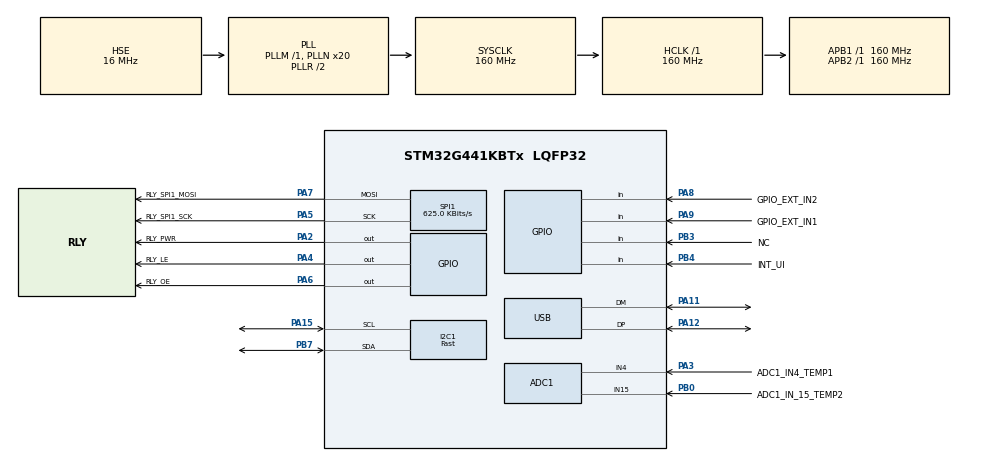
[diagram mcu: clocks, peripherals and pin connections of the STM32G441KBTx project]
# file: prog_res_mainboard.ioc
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ADC1.Channel-0\#ChannelRegularConversion=ADC_CHANNEL_VREFINT
ADC1.Channel-1\#ChannelRegularConversion=ADC_CHANNEL_TEMPSENSOR_ADC1
ADC1.Channel-2\#ChannelRegularConversion=ADC_CHANNEL_4
ADC1.Channel-3\#ChannelRegularConversion=ADC_CHANNEL_15
ADC1.ClockPrescaler=ADC_CLOCK_ASYNC_DIV16
ADC1.ContinuousConvMode=ENABLE
ADC1.DMAContinuousRequests=ENABLE
ADC1.NbrOfConversion=4
ADC1.NbrOfConversionFlag=1
ADC1.OffsetNumber-0\#ChannelRegularConversion=ADC_OFFSET_NONE
ADC1.OffsetNumber-1\#ChannelRegularConversion=ADC_OFFSET_NONE
ADC1.OffsetNumber-2\#ChannelRegularConversion=ADC_OFFSET_NONE
ADC1.OffsetNumber-3\#ChannelRegularConversion=ADC_OFFSET_NONE
ADC1.OversamplingMode=ENABLE
ADC1.Rank-0\#ChannelRegularConversion=1
ADC1.Rank-1\#ChannelRegularConversion=2
ADC1.Rank-2\#ChannelRegularConversion=3
ADC1.Rank-3\#ChannelRegularConversion=4
ADC1.Ratio=ADC_OVERSAMPLING_RATIO_256
ADC1.RightBitShift=ADC_RIGHTBITSHIFT_4
ADC1.SamplingTime-0\#ChannelRegularConversion=ADC_SAMPLETIME_640CYCLES_5
ADC1.SamplingTime-1\#ChannelRegularConversion=ADC_SAMPLETIME_640CYCLES_5
ADC1.SamplingTime-2\#ChannelRegularConversion=ADC_SAMPLETIME_640CYCLES_5
ADC1.SamplingTime-3\#ChannelRegularConversion=ADC_SAMPLETIME_640CYCLES_5
ADC1.master=1
Dma.ADC1.0.Direction=DMA_PERIPH_TO_MEMORY
Dma.ADC1.0.EventEnable=DISABLE
Dma.ADC1.0.Instance=DMA2_Channel1
Dma.ADC1.0.MemDataAlignment=DMA_MDATAALIGN_WORD
Dma.ADC1.0.MemInc=DMA_MINC_ENABLE
Dma.ADC1.0.Mode=DMA_CIRCULAR
Dma.ADC1.0.PeriphDataAlignment=DMA_PDATAALIGN_WORD
Dma.ADC1.0.PeriphInc=DMA_PINC_DISABLE
Dma.ADC1.0.Polarity=HAL_DMAMUX_REQ_GEN_RISING
Dma.ADC1.0.Priority=DMA_PRIORITY_LOW
Dma.ADC1.0.RequestNumber=1
Dma.ADC1.0.SignalID=NONE
Dma.ADC1.0.SyncEnable=DISABLE
Dma.ADC1.0.SyncPolarity=HAL_DMAMUX_SYNC_NO_EVENT
Dma.ADC1.0.SyncRequestNumber=1
Dma.ADC1.0.SyncSignalID=NONE
Dma.Request0=ADC1
FREERTOS.INCLUDE_uxTaskGetStackHighWaterMark=1
FREERTOS.INCLUDE_uxTaskPriorityGet=1
FREERTOS.INCLUDE_vTaskDelete=1
FREERTOS.INCLUDE_vTaskPrioritySet=1
FREERTOS.INCLUDE_xQueueGetMutexHolder=0
FREERTOS.INCLUDE_xSemaphoreGetMutexHolder=1
FREERTOS.INCLUDE_xTaskGetSchedulerState=1
FREERTOS.INCLUDE_xTaskResumeFromISR=0
FREERTOS.Mutexes01=i2cMutex,Static,i2cMutexControlBlock
FREERTOS.Queues01=keycodeQueue,16,uint8_t,0,Static,keycodeQueueBuffer,keycodeQueueControlBlock;encoderQueue,16,int16_t,0,Static,encoderQueueBuffer,encoderQueueControlBlock
FREERTOS.Tasks01=scpiTask,32,512,BASE_StartScpiTask,As weak,NULL,Static,scpiTaskBuffer,scpiTaskControlBlock;uiTask,24,512,BASE_StartUiTask,As weak,NULL,Static,uiTaskBuffer,uiTaskControlBlock
FREERTOS.Timers01=timer10ms,BASE_TimerTick_10ms,osTimerPeriodic,As weak,NULL,Static,timer10msControlBlock
FREERTOS.configENABLE_FPU=1
FREERTOS.configTOTAL_HEAP_SIZE=512
FREERTOS.configUSE_NEWLIB_REENTRANT=1
I2C1.CustomTiming=Disabled
I2C1.I2C_Fall_Time=300
I2C1.I2C_Rise_Time=300
I2C1.I2C_Speed_Mode=I2C_Fast
I2C1.Speed=200
I2C1.Timing=0x30FA1594
Mcu.Family=STM32G4
Mcu.Name=STM32G441KBTx
Mcu.Package=LQFP32
NVIC.ADC1_2_IRQn=true\:5\:0\:false\:false\:true\:true\:true\:true\:true
NVIC.DMA2_Channel1_IRQn=true\:5\:0\:false\:false\:true\:true\:false\:true\:true
NVIC.I2C1_ER_IRQn=true\:5\:0\:false\:false\:true\:true\:true\:true\:true
NVIC.I2C1_EV_IRQn=true\:5\:0\:false\:false\:true\:true\:true\:true\:true
NVIC.PriorityGroup=NVIC_PRIORITYGROUP_4
NVIC.SPI1_IRQn=true\:5\:0\:false\:false\:true\:true\:true\:true\:true
NVIC.TIM6_DAC_IRQn=true\:15\:0\:false\:false\:true\:false\:false\:true\:true
NVIC.TIM7_IRQn=true\:5\:0\:false\:false\:true\:true\:true\:true\:true
NVIC.TimeBase=TIM6_DAC_IRQn
NVIC.TimeBaseIP=TIM6
NVIC.USB_LP_IRQn=true\:5\:0\:false\:false\:true\:true\:false\:true\:true
PA11.Mode=Device
PA11.Signal=USB_DM
PA12.Mode=Device
PA12.Signal=USB_DP
PA13.Mode=Serial_Wire
PA13.Signal=SYS_JTMS-SWDIO
PA14.Mode=Serial_Wire
PA14.Signal=SYS_JTCK-SWCLK
PA15.Mode=I2C
PA15.Signal=I2C1_SCL
PA2.GPIO_Label=RLY_PWR
PA2.Signal=GPIO_Output
PA3.GPIO_Label=ADC1_IN4_TEMP1
PA3.Mode=IN4-Single-Ended
PA3.Signal=ADC1_IN4
PA4.GPIO_Label=RLY_LE
PA4.Signal=GPIO_Output
PA5.GPIO_Label=RLY_SPI1_SCK
PA5.Mode=TX_Only_Simplex_Unidirect_Master
PA5.Signal=SPI1_SCK
PA6.GPIO_Label=RLY_OE
PA6.Signal=GPIO_Output
PA7.GPIO_Label=RLY_SPI1_MOSI
PA7.Mode=TX_Only_Simplex_Unidirect_Master
PA7.Signal=SPI1_MOSI
PA8.GPIO_Label=GPIO_EXT_IN2
PA8.Signal=GPIO_Input
PA9.GPIO_Label=GPIO_EXT_IN1
PA9.Signal=GPIO_Input
PB0.GPIO_Label=ADC1_IN_15_TEMP2
PB0.Mode=IN15-Single-Ended
PB0.Signal=ADC1_IN15
PB3.GPIO_Label=NC
PB3.Signal=GPIO_Input
PB4.GPIO_Label=INT_UI
PB4.Signal=GPIO_Input
PB7.Mode=I2C
PB7.Signal=I2C1_SDA
PF0-OSC_IN.Mode=HSE-External-Oscillator
PF0-OSC_IN.Signal=RCC_OSC_IN
PF1-OSC_OUT.Mode=HSE-External-Oscillator
PF1-OSC_OUT.Signal=RCC_OSC_OUT
ProjectManager.HeapSize=0x180
ProjectManager.StackSize=0x300
ProjectManager.TargetToolchain=STM32CubeIDE
RCC.ADC12Freq_Value=160000000
RCC.AHBFreq_Value=160000000
RCC.APB1Freq_Value=160000000
RCC.APB1TimFreq_Value=160000000
RCC.APB2Freq_Value=160000000
RCC.APB2TimFreq_Value=160000000
RCC.CK48CLockSelection=RCC_USBCLKSOURCE_HSI48
RCC.CortexFreq_Value=160000000
RCC.EXTERNAL_CLOCK_VALUE=12288000
RCC.EnbaleCSS=true
RCC.HCLKFreq_Value=160000000
RCC.HSE_VALUE=16000000
RCC.HSI48_VALUE=48000000
RCC.HSI_VALUE=16000000
RCC.LSE_VALUE=32768
RCC.PLLN=20
RCC.PLLQ=RCC_PLLQ_DIV8
RCC.PLLSourceVirtual=RCC_PLLSOURCE_HSE
RCC.SYSCLKFreq_VALUE=160000000
RCC.SYSCLKSource=RCC_SYSCLKSOURCE_PLLCLK
RCC.USBFreq_Value=48000000
RCC.VCOOutputFreq_Value=320000000
SPI1.BaudRatePrescaler=SPI_BAUDRATEPRESCALER_256
SPI1.CalculateBaudRate=625.0 KBits/s
SPI1.DataSize=SPI_DATASIZE_16BIT
SPI1.Direction=SPI_DIRECTION_2LINES
SPI1.Mode=SPI_MODE_MASTER
SPI1.VirtualType=VM_MASTER
TIM7.AutoReloadPreload=TIM_AUTORELOAD_PRELOAD_ENABLE
TIM7.PeriodNoDither=64000-1
TIM7.Prescaler=25-1
USB_DEVICE.CLASS_NAME_FS=CDC
USB_DEVICE.VirtualMode=Cdc
USB_DEVICE.VirtualModeFS=Cdc_FS
VP_ADC1_TempSens_Input.Mode=IN-TempSens
VP_ADC1_Vref_Input.Mode=IN-Vrefint
VP_CRC_VS_CRC.Mode=CRC_Activate
VP_FREERTOS_VS_CMSIS_V2.Mode=CMSIS_V2
VP_SYS_VS_tim6.Mode=TIM6
VP_TIM7_VS_ClockSourceINT.Mode=Enable_Timer
VP_USB_DEVICE_VS_USB_DEVICE_CDC_FS.Mode=CDC_FS
board=custom

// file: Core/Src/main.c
/* USER CODE BEGIN Header */
/**
  ******************************************************************************
  * @file           : main.c
  * @brief          : Main program body
  ******************************************************************************
  * @attention
  *
  * Copyright (c) 2022 STMicroelectronics.
  * All rights reserved.
  *
  * This software is licensed under terms that can be found in the LICENSE file
  * in the root directory of this software component.
  * If no LICENSE file comes with this software, it is provided AS-IS.
  *
  ******************************************************************************
  */
/* USER CODE END Header */
#include "main.h"
#include "cmsis_os.h"
#include "usb_device.h"

/* USER CODE BEGIN Includes */
#include "base.h"
/* USER CODE END Includes */

typedef StaticTask_t osStaticThreadDef_t;
typedef StaticQueue_t osStaticMessageQDef_t;
typedef StaticTimer_t osStaticTimerDef_t;
typedef StaticSemaphore_t osStaticMutexDef_t;

ADC_HandleTypeDef hadc1;
DMA_HandleTypeDef hdma_adc1;

CRC_HandleTypeDef hcrc;

I2C_HandleTypeDef hi2c1;

SPI_HandleTypeDef hspi1;

TIM_HandleTypeDef htim7;

/* Definitions for scpiTask */
osThreadId_t scpiTaskHandle;
uint32_t scpiTaskBuffer[ 512 ];
osStaticThreadDef_t scpiTaskControlBlock;
const osThreadAttr_t scpiTask_attributes = {
  .name = "scpiTask",
  .stack_mem = &scpiTaskBuffer[0],
  .stack_size = sizeof(scpiTaskBuffer),
  .cb_mem = &scpiTaskControlBlock,
  .cb_size = sizeof(scpiTaskControlBlock),
  .priority = (osPriority_t) osPriorityAboveNormal,
};
/* Definitions for uiTask */
osThreadId_t uiTaskHandle;
uint32_t uiTaskBuffer[ 512 ];
osStaticThreadDef_t uiTaskControlBlock;
const osThreadAttr_t uiTask_attributes = {
  .name = "uiTask",
  .stack_mem = &uiTaskBuffer[0],
  .stack_size = sizeof(uiTaskBuffer),
  .cb_mem = &uiTaskControlBlock,
  .cb_size = sizeof(uiTaskControlBlock),
  .priority = (osPriority_t) osPriorityNormal,
};
/* Definitions for keycodeQueue */
osMessageQueueId_t keycodeQueueHandle;
uint8_t keycodeQueueBuffer[ 16 * sizeof( uint8_t ) ];
osStaticMessageQDef_t keycodeQueueControlBlock;
const osMessageQueueAttr_t keycodeQueue_attributes = {
  .name = "keycodeQueue",
  .cb_mem = &keycodeQueueControlBlock,
  .cb_size = sizeof(keycodeQueueControlBlock),
  .mq_mem = &keycodeQueueBuffer,
  .mq_size = sizeof(keycodeQueueBuffer)
};
/* Definitions for encoderQueue */
osMessageQueueId_t encoderQueueHandle;
uint8_t encoderQueueBuffer[ 16 * sizeof( int16_t ) ];
osStaticMessageQDef_t encoderQueueControlBlock;
const osMessageQueueAttr_t encoderQueue_attributes = {
  .name = "encoderQueue",
  .cb_mem = &encoderQueueControlBlock,
  .cb_size = sizeof(encoderQueueControlBlock),
  .mq_mem = &encoderQueueBuffer,
  .mq_size = sizeof(encoderQueueBuffer)
};
/* Definitions for timer10ms */
osTimerId_t timer10msHandle;
osStaticTimerDef_t timer10msControlBlock;
const osTimerAttr_t timer10ms_attributes = {
  .name = "timer10ms",
  .cb_mem = &timer10msControlBlock,
  .cb_size = sizeof(timer10msControlBlock),
};
/* Definitions for i2cMutex */
osMutexId_t i2cMutexHandle;
osStaticMutexDef_t i2cMutexControlBlock;
const osMutexAttr_t i2cMutex_attributes = {
  .name = "i2cMutex",
  .cb_mem = &i2cMutexControlBlock,
  .cb_size = sizeof(i2cMutexControlBlock),
};

void SystemClock_Config(void);
static void MX_GPIO_Init(void);
static void MX_DMA_Init(void);
static void MX_I2C1_Init(void);
static void MX_SPI1_Init(void);
static void MX_ADC1_Init(void);
static void MX_CRC_Init(void);
static void MX_TIM7_Init(void);
void BASE_StartScpiTask(void *argument);
void BASE_StartUiTask(void *argument);
void BASE_TimerTick_10ms(void *argument);

int main(void)
{

  /* MCU Configuration--------------------------------------------------------*/

  /* Reset of all peripherals, Initializes the Flash interface and the Systick. */
  HAL_Init();

  /* Configure the system clock */
  SystemClock_Config();

  /* Initialize all configured peripherals */
  MX_GPIO_Init();
  MX_DMA_Init();
  MX_I2C1_Init();
  MX_SPI1_Init();
  MX_ADC1_Init();
  MX_USB_Device_Init();
  MX_CRC_Init();
  MX_TIM7_Init();

  /* Init scheduler */
  osKernelInitialize();
  /* Create the mutex(es) */
  /* creation of i2cMutex */
  i2cMutexHandle = osMutexNew(&i2cMutex_attributes);

  /* Create the timer(s) */
  /* creation of timer10ms */
  timer10msHandle = osTimerNew(BASE_TimerTick_10ms, osTimerPeriodic, NULL, &timer10ms_attributes);

  /* USER CODE BEGIN RTOS_TIMERS */
  /* start timers, add new ones, ... */

  if (osTimerStart(timer10msHandle, 10) != osOK)
  {
	  // TODO: Add error handling
  }

  /* USER CODE END RTOS_TIMERS */

  /* Create the queue(s) */
  /* creation of keycodeQueue */
  keycodeQueueHandle = osMessageQueueNew (16, sizeof(uint8_t), &keycodeQueue_attributes);

  /* creation of encoderQueue */
  encoderQueueHandle = osMessageQueueNew (16, sizeof(int16_t), &encoderQueue_attributes);

  /* Create the thread(s) */
  /* creation of scpiTask */
  scpiTaskHandle = osThreadNew(BASE_StartScpiTask, NULL, &scpiTask_attributes);

  /* creation of uiTask */
  uiTaskHandle = osThreadNew(BASE_StartUiTask, NULL, &uiTask_attributes);

  /* USER CODE BEGIN RTOS_EVENTS */
  /* add events, ... */
  BASE_Init();
  /* USER CODE END RTOS_EVENTS */

  /* Start scheduler */
  osKernelStart();

  /* We should never get here as control is now taken by the scheduler */
  /* Infinite loop */
  while (1)
  {

  }
}

void SystemClock_Config(void)
{
  RCC_OscInitTypeDef RCC_OscInitStruct = {0};
  RCC_ClkInitTypeDef RCC_ClkInitStruct = {0};

  /** Configure the main internal regulator output voltage
  */
  HAL_PWREx_ControlVoltageScaling(PWR_REGULATOR_VOLTAGE_SCALE1_BOOST);

  /** Initializes the RCC Oscillators according to the specified parameters
  * in the RCC_OscInitTypeDef structure.
  */
  RCC_OscInitStruct.OscillatorType = RCC_OSCILLATORTYPE_HSI48|RCC_OSCILLATORTYPE_HSE;
  RCC_OscInitStruct.HSEState = RCC_HSE_ON;
  RCC_OscInitStruct.HSI48State = RCC_HSI48_ON;
  RCC_OscInitStruct.PLL.PLLState = RCC_PLL_ON;
  RCC_OscInitStruct.PLL.PLLSource = RCC_PLLSOURCE_HSE;
  RCC_OscInitStruct.PLL.PLLM = RCC_PLLM_DIV1;
  RCC_OscInitStruct.PLL.PLLN = 20;
  RCC_OscInitStruct.PLL.PLLP = RCC_PLLP_DIV2;
  RCC_OscInitStruct.PLL.PLLQ = RCC_PLLQ_DIV8;
  RCC_OscInitStruct.PLL.PLLR = RCC_PLLR_DIV2;
  if (HAL_RCC_OscConfig(&RCC_OscInitStruct) != HAL_OK)
  {
    Error_Handler();
  }

  /** Initializes the CPU, AHB and APB buses clocks
  */
  RCC_ClkInitStruct.ClockType = RCC_CLOCKTYPE_HCLK|RCC_CLOCKTYPE_SYSCLK
                              |RCC_CLOCKTYPE_PCLK1|RCC_CLOCKTYPE_PCLK2;
  RCC_ClkInitStruct.SYSCLKSource = RCC_SYSCLKSOURCE_PLLCLK;
  RCC_ClkInitStruct.AHBCLKDivider = RCC_SYSCLK_DIV1;
  RCC_ClkInitStruct.APB1CLKDivider = RCC_HCLK_DIV1;
  RCC_ClkInitStruct.APB2CLKDivider = RCC_HCLK_DIV1;

  if (HAL_RCC_ClockConfig(&RCC_ClkInitStruct, FLASH_LATENCY_4) != HAL_OK)
  {
    Error_Handler();
  }

  /** Enables the Clock Security System
  */
  HAL_RCC_EnableCSS();
}

static void MX_ADC1_Init(void)
{

  ADC_MultiModeTypeDef multimode = {0};
  ADC_ChannelConfTypeDef sConfig = {0};

  /** Common config
  */
  hadc1.Instance = ADC1;
  hadc1.Init.ClockPrescaler = ADC_CLOCK_ASYNC_DIV16;
  hadc1.Init.Resolution = ADC_RESOLUTION_12B;
  hadc1.Init.DataAlign = ADC_DATAALIGN_RIGHT;
  hadc1.Init.GainCompensation = 0;
  hadc1.Init.ScanConvMode = ADC_SCAN_ENABLE;
  hadc1.Init.EOCSelection = ADC_EOC_SINGLE_CONV;
  hadc1.Init.LowPowerAutoWait = DISABLE;
  hadc1.Init.ContinuousConvMode = ENABLE;
  hadc1.Init.NbrOfConversion = 4;
  hadc1.Init.DiscontinuousConvMode = DISABLE;
  hadc1.Init.ExternalTrigConv = ADC_SOFTWARE_START;
  hadc1.Init.ExternalTrigConvEdge = ADC_EXTERNALTRIGCONVEDGE_NONE;
  hadc1.Init.DMAContinuousRequests = ENABLE;
  hadc1.Init.Overrun = ADC_OVR_DATA_PRESERVED;
  hadc1.Init.OversamplingMode = ENABLE;
  hadc1.Init.Oversampling.Ratio = ADC_OVERSAMPLING_RATIO_256;
  hadc1.Init.Oversampling.RightBitShift = ADC_RIGHTBITSHIFT_4;
  hadc1.Init.Oversampling.TriggeredMode = ADC_TRIGGEREDMODE_SINGLE_TRIGGER;
  hadc1.Init.Oversampling.OversamplingStopReset = ADC_REGOVERSAMPLING_CONTINUED_MODE;
  if (HAL_ADC_Init(&hadc1) != HAL_OK)
  {
    Error_Handler();
  }

  /** Configure the ADC multi-mode
  */
  multimode.Mode = ADC_MODE_INDEPENDENT;
  if (HAL_ADCEx_MultiModeConfigChannel(&hadc1, &multimode) != HAL_OK)
  {
    Error_Handler();
  }

  /** Configure Regular Channel
  */
  sConfig.Channel = ADC_CHANNEL_VREFINT;
  sConfig.Rank = ADC_REGULAR_RANK_1;
  sConfig.SamplingTime = ADC_SAMPLETIME_640CYCLES_5;
  sConfig.SingleDiff = ADC_SINGLE_ENDED;
  sConfig.OffsetNumber = ADC_OFFSET_NONE;
  sConfig.Offset = 0;
  if (HAL_ADC_ConfigChannel(&hadc1, &sConfig) != HAL_OK)
  {
    Error_Handler();
  }

  /** Configure Regular Channel
  */
  sConfig.Channel = ADC_CHANNEL_TEMPSENSOR_ADC1;
  sConfig.Rank = ADC_REGULAR_RANK_2;
  if (HAL_ADC_ConfigChannel(&hadc1, &sConfig) != HAL_OK)
  {
    Error_Handler();
  }

  /** Configure Regular Channel
  */
  sConfig.Channel = ADC_CHANNEL_4;
  sConfig.Rank = ADC_REGULAR_RANK_3;
  if (HAL_ADC_ConfigChannel(&hadc1, &sConfig) != HAL_OK)
  {
    Error_Handler();
  }

  /** Configure Regular Channel
  */
  sConfig.Channel = ADC_CHANNEL_15;
  sConfig.Rank = ADC_REGULAR_RANK_4;
  if (HAL_ADC_ConfigChannel(&hadc1, &sConfig) != HAL_OK)
  {
    Error_Handler();
  }

}

static void MX_CRC_Init(void)
{

  hcrc.Instance = CRC;
  hcrc.Init.DefaultPolynomialUse = DEFAULT_POLYNOMIAL_ENABLE;
  hcrc.Init.DefaultInitValueUse = DEFAULT_INIT_VALUE_ENABLE;
  hcrc.Init.InputDataInversionMode = CRC_INPUTDATA_INVERSION_NONE;
  hcrc.Init.OutputDataInversionMode = CRC_OUTPUTDATA_INVERSION_DISABLE;
  hcrc.InputDataFormat = CRC_INPUTDATA_FORMAT_BYTES;
  if (HAL_CRC_Init(&hcrc) != HAL_OK)
  {
    Error_Handler();
  }

}

static void MX_I2C1_Init(void)
{

  hi2c1.Instance = I2C1;
  hi2c1.Init.Timing = 0x30FA1594;
  hi2c1.Init.OwnAddress1 = 0;
  hi2c1.Init.AddressingMode = I2C_ADDRESSINGMODE_7BIT;
  hi2c1.Init.DualAddressMode = I2C_DUALADDRESS_DISABLE;
  hi2c1.Init.OwnAddress2 = 0;
  hi2c1.Init.OwnAddress2Masks = I2C_OA2_NOMASK;
  hi2c1.Init.GeneralCallMode = I2C_GENERALCALL_DISABLE;
  hi2c1.Init.NoStretchMode = I2C_NOSTRETCH_DISABLE;
  if (HAL_I2C_Init(&hi2c1) != HAL_OK)
  {
    Error_Handler();
  }

  /** Configure Analogue filter
  */
  if (HAL_I2CEx_ConfigAnalogFilter(&hi2c1, I2C_ANALOGFILTER_ENABLE) != HAL_OK)
  {
    Error_Handler();
  }

  /** Configure Digital filter
  */
  if (HAL_I2CEx_ConfigDigitalFilter(&hi2c1, 0) != HAL_OK)
  {
    Error_Handler();
  }

}

static void MX_SPI1_Init(void)
{

  /* SPI1 parameter configuration*/
  hspi1.Instance = SPI1;
  hspi1.Init.Mode = SPI_MODE_MASTER;
  hspi1.Init.Direction = SPI_DIRECTION_2LINES;
  hspi1.Init.DataSize = SPI_DATASIZE_16BIT;
  hspi1.Init.CLKPolarity = SPI_POLARITY_LOW;
  hspi1.Init.CLKPhase = SPI_PHASE_1EDGE;
  hspi1.Init.NSS = SPI_NSS_SOFT;
  hspi1.Init.BaudRatePrescaler = SPI_BAUDRATEPRESCALER_256;
  hspi1.Init.FirstBit = SPI_FIRSTBIT_MSB;
  hspi1.Init.TIMode = SPI_TIMODE_DISABLE;
  hspi1.Init.CRCCalculation = SPI_CRCCALCULATION_DISABLE;
  hspi1.Init.CRCPolynomial = 7;
  hspi1.Init.CRCLength = SPI_CRC_LENGTH_DATASIZE;
  hspi1.Init.NSSPMode = SPI_NSS_PULSE_ENABLE;
  if (HAL_SPI_Init(&hspi1) != HAL_OK)
  {
    Error_Handler();
  }

}

static void MX_TIM7_Init(void)
{

  TIM_MasterConfigTypeDef sMasterConfig = {0};

  htim7.Instance = TIM7;
  htim7.Init.Prescaler = 25-1;
  htim7.Init.CounterMode = TIM_COUNTERMODE_UP;
  htim7.Init.Period = 63999;
  htim7.Init.AutoReloadPreload = TIM_AUTORELOAD_PRELOAD_ENABLE;
  if (HAL_TIM_Base_Init(&htim7) != HAL_OK)
  {
    Error_Handler();
  }
  sMasterConfig.MasterOutputTrigger = TIM_TRGO_RESET;
  sMasterConfig.MasterSlaveMode = TIM_MASTERSLAVEMODE_DISABLE;
  if (HAL_TIMEx_MasterConfigSynchronization(&htim7, &sMasterConfig) != HAL_OK)
  {
    Error_Handler();
  }

}

static void MX_DMA_Init(void)
{

  /* DMA controller clock enable */
  __HAL_RCC_DMAMUX1_CLK_ENABLE();
  __HAL_RCC_DMA2_CLK_ENABLE();

  /* DMA interrupt init */
  /* DMA2_Channel1_IRQn interrupt configuration */
  HAL_NVIC_SetPriority(DMA2_Channel1_IRQn, 5, 0);
  HAL_NVIC_EnableIRQ(DMA2_Channel1_IRQn);

}

static void MX_GPIO_Init(void)
{
  GPIO_InitTypeDef GPIO_InitStruct = {0};

  /* GPIO Ports Clock Enable */
  __HAL_RCC_GPIOF_CLK_ENABLE();
  __HAL_RCC_GPIOA_CLK_ENABLE();
  __HAL_RCC_GPIOB_CLK_ENABLE();

  /*Configure GPIO pin Output Level */
  HAL_GPIO_WritePin(GPIOA, RLY_PWR_Pin|RLY_LE_Pin|RLY_OE_Pin, GPIO_PIN_RESET);

  /*Configure GPIO pins : RLY_PWR_Pin RLY_LE_Pin RLY_OE_Pin */
  GPIO_InitStruct.Pin = RLY_PWR_Pin|RLY_LE_Pin|RLY_OE_Pin;
  GPIO_InitStruct.Mode = GPIO_MODE_OUTPUT_PP;
  GPIO_InitStruct.Pull = GPIO_NOPULL;
  GPIO_InitStruct.Speed = GPIO_SPEED_FREQ_LOW;
  HAL_GPIO_Init(GPIOA, &GPIO_InitStruct);

  /*Configure GPIO pins : GPIO_EXT_IN2_Pin GPIO_EXT_IN1_Pin */
  GPIO_InitStruct.Pin = GPIO_EXT_IN2_Pin|GPIO_EXT_IN1_Pin;
  GPIO_InitStruct.Mode = GPIO_MODE_INPUT;
  GPIO_InitStruct.Pull = GPIO_NOPULL;
  HAL_GPIO_Init(GPIOA, &GPIO_InitStruct);

  /*Configure GPIO pins : NC_Pin INT_UI_Pin */
  GPIO_InitStruct.Pin = NC_Pin|INT_UI_Pin;
  GPIO_InitStruct.Mode = GPIO_MODE_INPUT;
  GPIO_InitStruct.Pull = GPIO_NOPULL;
  HAL_GPIO_Init(GPIOB, &GPIO_InitStruct);

}

__weak void BASE_StartScpiTask(void *argument)
{
  for(;;)
  {
    osDelay(1);
  }
}

__weak void BASE_StartUiTask(void *argument)
{
  for(;;)
  {
    osDelay(1);
  }
}

/* BASE_TimerTick_10ms function */
__weak void BASE_TimerTick_10ms(void *argument)
{
}

void HAL_TIM_PeriodElapsedCallback(TIM_HandleTypeDef *htim)
{
  /* USER CODE BEGIN Callback 0 */
	if (htim->Instance == TIM7)
	{
		BASE_AppTick();
	}
  /* USER CODE END Callback 0 */
  if (htim->Instance == TIM6) {
    HAL_IncTick();
  }
}

void Error_Handler(void)
{
  __disable_irq();
  while (1)
  {
  }
}
